# AT91SAM9M11 register map
Vendor: Atmel; File version: 20130207
CPU: 
Registers are 32-bit, read-write, no defined reset value unless marked. A register's access mark holds for its fields unless they carry their own. Offsets are from the block's base; [hi:lo] are bit positions; {n}, {i} and the like mark numbered series; 'fields as' and 'values as' point back to an identical list.

## DMAC — DMA Controller
Base 0xFFFFEC00; register names take the prefix DMAC_
0x00 GCFG reset 0x10 — DMAC Global Configuration Register
  [4] ARB_CFG
0x04 EN reset 0x0 — DMAC Enable Register
  [0] ENABLE
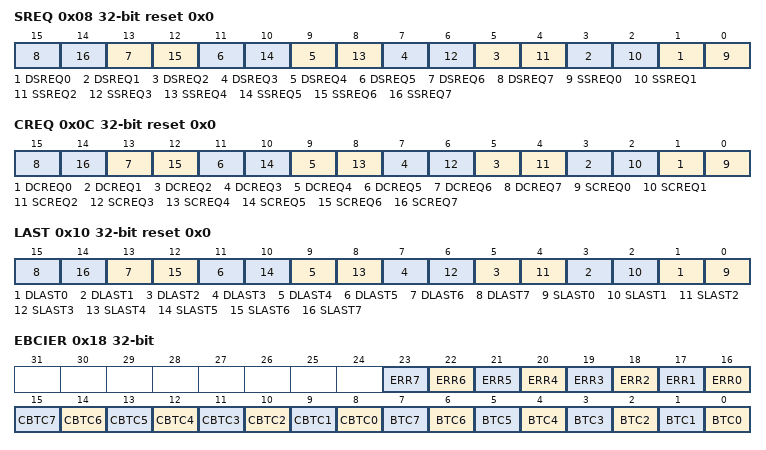
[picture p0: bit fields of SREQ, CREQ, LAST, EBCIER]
0x08 SREQ reset 0x0 — DMAC Software Single Request Register
  [2n+1] DSREQ{n} (n=0..7), [2n] SSREQ{n} (n=0..7)
0x0C CREQ reset 0x0 — DMAC Software Chunk Transfer Request Register
  [2n+1] DCREQ{n} (n=0..7), [2n] SCREQ{n} (n=0..7)
0x10 LAST reset 0x0 — DMAC Software Last Transfer Flag Register
  [2n+1] DLAST{n} (n=0..7), [2n] SLAST{n} (n=0..7)
0x18 EBCIER wo — DMAC Error, Chained Buffer transfer completed and Buffer transfer completed Interrupt Enable register.
  [n+16] ERR{n} (n=0..7) — Access Error [7:0]
  [n+8] CBTC{n} (n=0..7) — Chained Buffer Transfer Completed [7:0]
  [n] BTC{n} (n=0..7) — Buffer Transfer Completed [7:0]
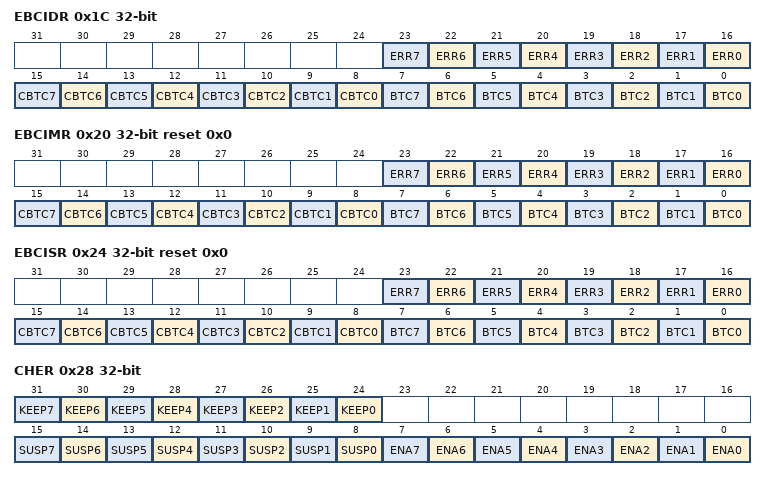
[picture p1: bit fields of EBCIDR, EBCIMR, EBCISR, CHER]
0x1C EBCIDR wo — DMAC Error, Chained Buffer transfer completed and Buffer transfer completed Interrupt Disable register.
  fields as EBCIER
0x20 EBCIMR ro reset 0x0 — DMAC Error, Chained Buffer transfer completed and Buffer transfer completed Mask Register.
  fields as EBCIER
0x24 EBCISR ro reset 0x0 — DMAC Error, Chained Buffer transfer completed and Buffer transfer completed Status Register.
  fields as EBCIER
0x28 CHER wo — DMAC Channel Handler Enable Register
  [n+24] KEEP{n} (n=0..7) — [7:0]
  [n+8] SUSP{n} (n=0..7) — [7:0]
  [n] ENA{n} (n=0..7) — [7:0]
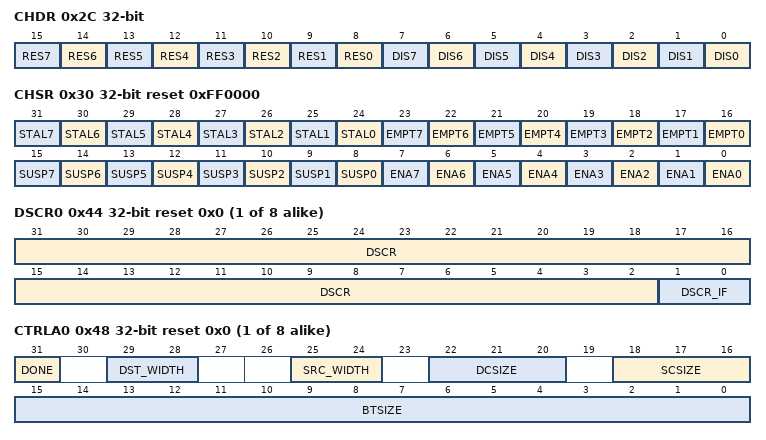
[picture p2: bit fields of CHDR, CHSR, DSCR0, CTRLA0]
0x2C CHDR wo — DMAC Channel Handler Disable Register
  [n+8] RES{n} (n=0..7) — [7:0]
  [n] DIS{n} (n=0..7) — [7:0]
0x30 CHSR ro reset 0xFF0000 — DMAC Channel Handler Status Register
  [n+24] STAL{n} (n=0..7) — [7:0]
  [n+16] EMPT{n} (n=0..7) — [7:0]
  [n+8] SUSP{n} (n=0..7) — [7:0]
  [n] ENA{n} (n=0..7) — [7:0]
{0x3C+0x28*i} SADDR{i} reset 0x0 (i=0..7) — DMAC Channel Source Address Register (ch_num = {i})
  [31:0] SADDR
{0x40+0x28*i} DADDR{i} reset 0x0 (i=0..7) — DMAC Channel Destination Address Register (ch_num = {i})
  [31:0] DADDR
{0x44+0x28*i} DSCR{i} reset 0x0 (i=0..7) — DMAC Channel Descriptor Address Register (ch_num = {i})
  [31:2] DSCR
  [1:0] DSCR_IF
    0=AHB_IFO (The buffer transfer descriptor is fetched via AHB-Lite Interface 0); 1=AHB_IF1 (The buffer transfer descriptor is fetched via AHB-Lite Interface 1); 2=AHB_IF2 (The buffer transfer descriptor is fetched via AHB-Lite Interface 2)
{0x48+0x28*i} CTRLA{i} reset 0x0 (i=0..7) — DMAC Channel Control A Register (ch_num = {i})
  [31] DONE
  [29:28] DST_WIDTH
    0=BYTE (the transfer size is set to 8-bit width); 1=HALF_WORD (the transfer size is set to 16-bit width); 2=WORD (the transfer size is set to 32-bit width)
  [25:24] SRC_WIDTH
    values as DST_WIDTH
  [22:20] DCSIZE
    0=CHK_1 (1 data transferred); 1=CHK_4 (4 data transferred); 2=CHK_8 (8 data transferred); 3=CHK_16 (16 data transferred); 4=CHK_32 (32 data transferred); 5=CHK_64 (64 data transferred); 6=CHK_128 (128 data transferred); 7=CHK_256 (256 data transferred)
  [18:16] SCSIZE
    values as DCSIZE
  [15:0] BTSIZE
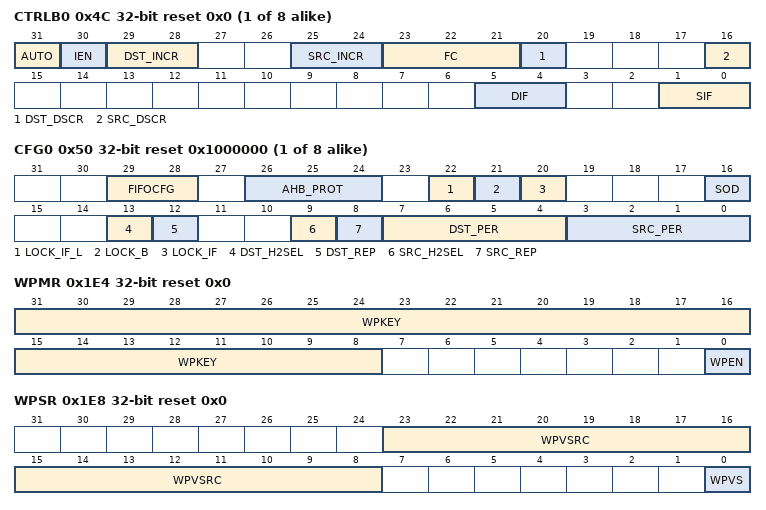
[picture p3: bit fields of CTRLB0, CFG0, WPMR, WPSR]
{0x4C+0x28*i} CTRLB{i} reset 0x0 (i=0..7) — DMAC Channel Control B Register (ch_num = {i})
  [31] AUTO
  [30] IEN
  [29:28] DST_INCR
    0=INCREMENTING (The destination address is incremented); 1=DECREMENTING (The destination address is decremented); 2=FIXED (The destination address remains unchanged)
  [25:24] SRC_INCR
    0=INCREMENTING (The source address is incremented); 1=DECREMENTING (The source address is decremented); 2=FIXED (The source address remains unchanged)
  [23:21] FC
    0=MEM2MEM_DMA_FC (Memory-to-Memory Transfer DMAC is flow controller); 1=MEM2PER_DMA_FC (Memory-to-Peripheral Transfer DMAC is flow controller); 2=PER2MEM_DMA_FC (Peripheral-to-Memory Transfer DMAC is flow controller); 3=PER2PER_DMA_FC (Peripheral-to-Peripheral Transfer DMAC is flow controller); 4=PER2MEM_PER_FC (Peripheral-to-Memory Transfer DMAC is flow controller); 5=MEM2PER_PER_FC (Memory-to-Peripheral Transfer DMAC is flow controller); 6=PER2PER_SPER_FC (Peripheral-to-Peripheral Transfer DMAC is flow controller); 7=PER2PER_DPER_FC (Peripheral-to-Peripheral Transfer DMAC is flow controller)
  [20] DST_DSCR
  [16] SRC_DSCR
  [5:4] DIF — Destination Interface Selection Field
    0=AHB_IFO (The destination transfer is done via AHB-Lite Interface 0); 1=AHB_IF1 (The destination transfer is done via AHB-Lite Interface 1); 2=AHB_IF2 (The destination transfer is done via AHB-Lite Interface 2)
  [1:0] SIF — Source Interface Selection Field
    0=AHB_IFO (The source transfer is done via AHB-Lite Interface 0); 1=AHB_IF1 (The source transfer is done via AHB-Lite Interface 1); 2=AHB_IF2 (The source transfer is done via AHB-Lite Interface 2)
{0x50+0x28*i} CFG{i} reset 0x1000000 (i=0..7) — DMAC Channel Configuration Register (ch_num = {i})
  [29:28] FIFOCFG
    0=ALAP_CFG (The largest defined length AHB burst is performed on the destination AHB interface.); 1=HALF_CFG (When half FIFO size is available/filled, a source/destination request is serviced.); 2=ASAP_CFG (When there is enough space/data available to perform a single AHB access, then the request is serviced.)
  [26:24] AHB_PROT
  [22] LOCK_IF_L
  [21] LOCK_B
  [20] LOCK_IF
  [16] SOD
  [13] DST_H2SEL
  [12] DST_REP
  [9] SRC_H2SEL
  [8] SRC_REP
  [7:4] DST_PER
  [3:0] SRC_PER
0x1E4 WPMR reset 0x0 — Write Protect Mode Register
  [31:8] WPKEY
  [0] WPEN — Write Protect Enable
0x1E8 WPSR ro reset 0x0 — Write Protect Status Register
  [23:8] WPVSRC — Write Protect Violation Source
  [0] WPVS
